# CM_CORE__COREAON register map
Vendor: Texas Instruments
Peripheral module from a debugger description file (folder am572x).
Registers are 32-bit, access per field, reset 0x0 unless marked. A register's access mark holds for its fields unless they carry their own. Offsets are as the file gives them; lines under a group give offsets from that group; [hi:lo] are bit positions; {n}, {i} and the like mark numbered series; 'fields as' and 'values as' point back to an identical list; <NAME> marks a mode.

## CM_CORE__COREAON
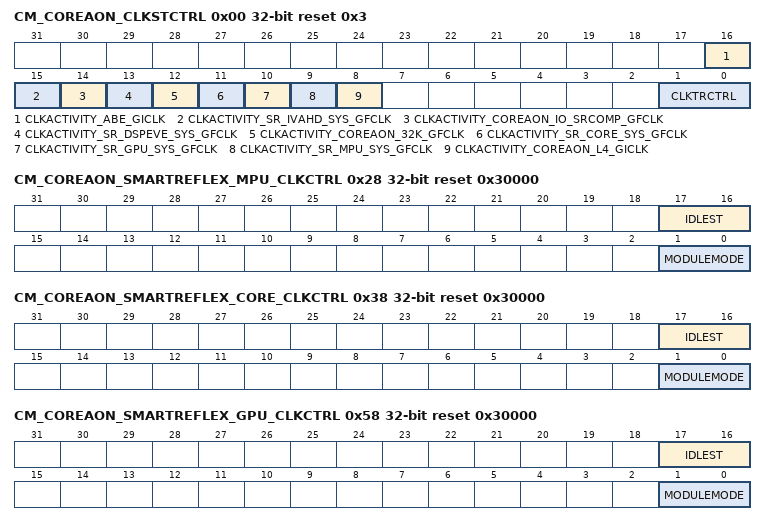
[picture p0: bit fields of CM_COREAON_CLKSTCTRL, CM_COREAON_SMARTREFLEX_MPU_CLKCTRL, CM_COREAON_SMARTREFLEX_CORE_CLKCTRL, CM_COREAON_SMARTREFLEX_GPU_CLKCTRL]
0x00 CM_COREAON_CLKSTCTRL access not given reset 0x3 — This register enables the domain power state transition. It controls the HW supervised domain power state transition between ON-ACTIVE and ON-INACTIVE states. It also hold one status bit per clock input of the domain.
  [16] CLKACTIVITY_ABE_GICLK ro — This field indicates the state of the ABE_GICLK clock input of the domain. [warm reset insensitive]
    0=INACT (Corresponding clock is definitely gated); 1=ACT (Corresponding clock is running or gating/ungating transition is on-going)
  [15] CLKACTIVITY_SR_IVAHD_SYS_GFCLK ro — This field indicates the state of the SR_IVAHD_SYS_GFCLK clock input of the domain. [warm reset insensitive]
    0=ACT (Corresponding clock is definitely gated); 1=ACT (Corresponding clock is running or gating/ungating transition is on-going)
  [14] CLKACTIVITY_COREAON_IO_SRCOMP_GFCLK ro — This field indicates the state of the COREAON_IO_SRCOMP_GFCLK clock in the domain. [warm reset insensitive]
    values as CLKACTIVITY_SR_IVAHD_SYS_GFCLK
  [13] CLKACTIVITY_SR_DSPEVE_SYS_GFCLK ro — This field indicates the state of the SR_DSPEVE_SYS_GFCLK clock input of the domain. [warm reset insensitive]
    0=Corresponding_clock_is_definitely_gated; 1=Corresponding clock is running or gating/ungating transition is on-going
  [12] CLKACTIVITY_COREAON_32K_GFCLK ro — This field indicates the state of the COREAON_32K_GFCLK clock in the domain. [warm reset insensitive]
    values as CLKACTIVITY_ABE_GICLK
  [11] CLKACTIVITY_SR_CORE_SYS_GFCLK ro — This field indicates the state of the SR_CORE_SYS_GFCLK clock input of the domain. [warm reset insensitive]
    values as CLKACTIVITY_SR_DSPEVE_SYS_GFCLK
  [10] CLKACTIVITY_SR_GPU_SYS_GFCLK ro — This field indicates the state of the SR_GPU_SYS_GFCLK clock input of the domain. [warm reset insensitive]
    values as CLKACTIVITY_SR_DSPEVE_SYS_GFCLK
  [9] CLKACTIVITY_SR_MPU_SYS_GFCLK ro — This field indicates the state of the SR_MPU_SYS_GFCLK clock input of the domain. [warm reset insensitive]
    values as CLKACTIVITY_SR_DSPEVE_SYS_GFCLK
  [8] CLKACTIVITY_COREAON_L4_GICLK ro — This field indicates the state of the COREAON_L4_GICLK clock of the domain. [warm reset insensitive]
    values as CLKACTIVITY_SR_DSPEVE_SYS_GFCLK
  [1:0] CLKTRCTRL rw — Controls the clock state transition of the COREAON clock domain.
    0=NO_SLEEP (NO_SLEEP: Sleep transition cannot be initiated. Wakeup transition may however occur.); 2=SW_WKUP (SW_WKUP: Start a software forced wake-up transition on the domain.); 3=HW_AUTO (HW_AUTO: Automatic transition is enabled. Sleep and wakeup transition are based upon hardware conditions.)
0x28 CM_COREAON_SMARTREFLEX_MPU_CLKCTRL reset 0x30000 — This register manages the SR_MPU clocks.
  [17:16] IDLEST ro — Module idle status. [warm reset insensitive]
    0=FUNC (Module is fully functional, including OCP); 1=TRANS (Module is performing transition: wakeup, or sleep, or sleep abortion); 2=IDLE (Module is in Idle mode (only OCP part). It is functional if using separate functional clock); 3=DISABLE (Module is disabled and cannot be accessed)
  [1:0] MODULEMODE rw — Control the way mandatory clocks are managed.
    0=DISABLED (Module is disabled by SW. Any OCP access to module results in an error, except if resulting from a module wakeup (asynchronous wakeup).); 2=ENABLE (Module is explicitly enabled. Interface clock (if not used for functions) may be gated according to the clock domain state. Functional clocks are guarantied to stay present. As long as in this configuration, power domain sleep transition cannot happen.)
0x38 CM_COREAON_SMARTREFLEX_CORE_CLKCTRL reset 0x30000 — This register manages the SR_CORE clocks.
  fields as CM_COREAON_SMARTREFLEX_MPU_CLKCTRL
0x40 CM_COREAON_USB_PHY1_CORE_CLKCTRL — This register manages the USB PHY 32KHz clock.
  [8] OPTFCLKEN_CLK32K rw — Optional functional clock control.
    0=FCLK_DIS (Optional functional clock is disabled); 1=FCLK_EN (Optional functional clock is enabled)
0x50 CM_COREAON_IO_SRCOMP_CLKCTRL — This register manages the clock delivered to the IO Slew rate compensation cells. [warm reset insensitive]
  [8] CLKEN_SRCOMP_FCLK rw — Functional clock control.
    0=FCLK_DIS (Functional clock is disabled); 1=FCLK_EN (Functional clock is enabled.)
0x58 CM_COREAON_SMARTREFLEX_GPU_CLKCTRL reset 0x30000 — This register manages the SR_GPU clocks.
  fields as CM_COREAON_SMARTREFLEX_MPU_CLKCTRL
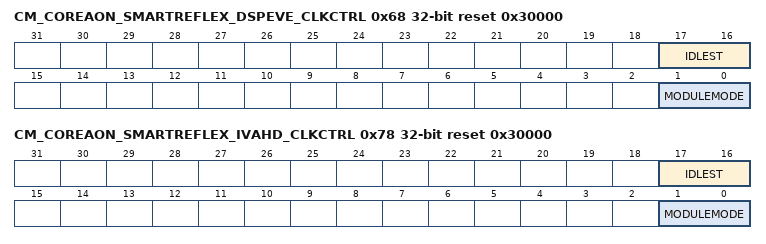
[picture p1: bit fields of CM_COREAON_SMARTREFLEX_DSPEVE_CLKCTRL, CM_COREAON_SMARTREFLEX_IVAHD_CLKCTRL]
0x68 CM_COREAON_SMARTREFLEX_DSPEVE_CLKCTRL reset 0x30000 — This register manages the SR_DSPEVE clocks.
  fields as CM_COREAON_SMARTREFLEX_MPU_CLKCTRL
0x78 CM_COREAON_SMARTREFLEX_IVAHD_CLKCTRL reset 0x30000 — This register manages the SR_IVAHD clocks.
  fields as CM_COREAON_SMARTREFLEX_MPU_CLKCTRL
0x88 CM_COREAON_USB_PHY2_CORE_CLKCTRL — This register manages the USB PHY 32KHz clock.
  fields as CM_COREAON_USB_PHY1_CORE_CLKCTRL
0x98 CM_COREAON_USB_PHY3_CORE_CLKCTRL — This register manages the USB PHY 32KHz clock.
  fields as CM_COREAON_USB_PHY1_CORE_CLKCTRL
0xA0 CM_COREAON_CLKOUTMUX1_CLKCTRL — Used for controlling the CLKOUTMUX 1 gate.
  [8] OPTFCLKEN_CLKOUTMUX1_CLK rw — Optional functional clock control.
    values as CM_COREAON_USB_PHY1_CORE_CLKCTRL.OPTFCLKEN_CLK32K
0xB0 CM_COREAON_CLKOUTMUX2_CLKCTRL — Used for controlling the CLKOUTMUX 2 gate.
  [8] OPTFCLKEN_CLKOUTMUX2_CLK rw — Optional functional clock control.
    values as CM_COREAON_USB_PHY1_CORE_CLKCTRL.OPTFCLKEN_CLK32K
0xC0 CM_COREAON_L3INIT_60M_GFCLK_CLKCTRL — Used for controlling the L3INIT_60M_GFCLK gate.
  [8] OPTFCLKEN_L3INIT_60M_GFCLK rw — Optional functional clock control; used to control the clock of USB2PHY2.
    values as CM_COREAON_USB_PHY1_CORE_CLKCTRL.OPTFCLKEN_CLK32K
0xD0 CM_COREAON_ABE_GICLK_CLKCTRL — Used for controlling ABE_GICLK gate.
  [8] OPTFCLKEN_ABE_GICLK rw — Optional functional clock control.
    values as CM_COREAON_USB_PHY1_CORE_CLKCTRL.OPTFCLKEN_CLK32K
